VERSION ""

NS_ :

BS_:

BU_: ECU AMKmotor_1

BO_ 3221225472 VECTOR__INDEPENDENT_SIG_MSG: 0 Vector__XXX
 SG_ LogicState_RR : 0|4@1+ (1,0) [0|15] "" Vector__XXX
 SG_ LogicState_RL : 0|4@1+ (1,0) [0|15] "" Vector__XXX
 SG_ LogicState_FR : 0|4@1+ (1,0) [0|15] "" Vector__XXX
 SG_ LogicState_FL : 0|4@1+ (1,0) [0|15] "" Vector__XXX
 SG_ FR_AMK_bEnable : 0|1@1+ (1,0) [0|1] "" Vector__XXX
 SG_ FL_AMK_bEnable : 0|1@1+ (1,0) [0|1] "" Vector__XXX
 SG_ RR_AMK_bEnable : 0|1@1+ (1,0) [0|1] "" Vector__XXX
 SG_ RL_AMK_bEnable : 0|1@1+ (1,0) [0|1] "" Vector__XXX
 SG_ FR_AMK_bQuitInverterOn : 0|1@1+ (1,0) [0|1] "" Vector__XXX
 SG_ FL_AMK_bQuitInverterOn : 0|1@1+ (1,0) [0|1] "" Vector__XXX
 SG_ RR_AMK_bQuitInverterOn : 0|1@1+ (1,0) [0|1] "" Vector__XXX
 SG_ RL_AMK_bQuitInverterOn : 0|1@1+ (1,0) [0|1] "" Vector__XXX
 SG_ FR_AMK_bQuitDcOn : 0|1@1+ (1,0) [0|1] "" Vector__XXX
 SG_ FL_AMK_bQuitDcOn : 0|1@1+ (1,0) [0|1] "" Vector__XXX
 SG_ RR_AMK_bQuitDcOn : 0|1@1+ (1,0) [0|1] "" Vector__XXX
 SG_ RL_AMK_bQuitDcOn : 0|1@1+ (1,0) [0|1] "" Vector__XXX
 SG_ FR_AMK_bSystemReady : 0|1@1+ (1,0) [0|1] "" Vector__XXX
 SG_ FL_AMK_bSystemReady : 0|1@1+ (1,0) [0|1] "" Vector__XXX
 SG_ RR_AMK_bSystemReady : 0|1@1+ (1,0) [0|1] "" Vector__XXX
 SG_ RL_AMK_bSystemReady : 0|1@1+ (1,0) [0|1] "" Vector__XXX
 SG_ FR_AMK_bError : 0|1@1+ (1,0) [0|1] "" Vector__XXX
 SG_ FL_AMK_bError : 0|1@1+ (1,0) [0|1] "" Vector__XXX
 SG_ RR_AMK_bError : 0|1@1+ (1,0) [0|1] "" Vector__XXX
 SG_ RL_AMK_bError : 0|1@1+ (1,0) [0|1] "" Vector__XXX
 SG_ ModeFlag : 0|4@1- (1,0) [-8|7] "" Vector__XXX
 SG_ FR_IGBT_temperature : 0|16@1- (0.1,0) [-3276.8|3276.7] "°" Vector__XXX
 SG_ FL_IGBT_temperature : 0|16@1- (0.1,0) [-3276.8|3276.7] "°" Vector__XXX
 SG_ RR_IGBT_temperature : 0|16@1- (0.1,0) [-3276.8|3276.7] "°" Vector__XXX
 SG_ RL_IGBT_temperature : 0|16@1- (0.1,0) [-3276.8|3276.7] "°" Vector__XXX
 SG_ FR_Inverter_temperature : 0|16@1- (0.1,0) [-3276.8|3276.7] "°" Vector__XXX
 SG_ FL_Inverter_temperature : 0|16@1- (0.1,0) [-3276.8|3276.7] "°" Vector__XXX
 SG_ RR_Inverter_temperature : 0|16@1- (0.1,0) [-3276.8|3276.7] "°" Vector__XXX
 SG_ RL_Inverter_temperature : 0|16@1- (0.1,0) [-3276.8|3276.7] "°" Vector__XXX
 SG_ FR_Motor_temperature : 0|16@1- (0.1,0) [-3276.8|3276.7] "°" Vector__XXX
 SG_ FL_Motor_temperature : 0|16@1- (0.1,0) [-3276.8|3276.7] "°" Vector__XXX
 SG_ RR_Motor_temperature : 0|16@1- (0.1,0) [-3276.8|3276.7] "°" Vector__XXX
 SG_ RL_Motor_temperature : 0|16@1- (0.1,0) [-3276.8|3276.7] "°" Vector__XXX
 SG_ FR_ActualVelocity : 0|16@1- (1,0) [-32768|32767] "" Vector__XXX
 SG_ FL_ActualVelocity : 0|16@1- (1,0) [-32768|32767] "" Vector__XXX
 SG_ RR_ActualVelocity : 0|16@1- (1,0) [-32768|32767] "" Vector__XXX
 SG_ RL_ActualVelocity : 0|16@1- (1,0) [-32768|32767] "" Vector__XXX
 SG_ FR_ActualTorque : 0|16@1- (1,0) [-32768|32767] "0.1%Mn" Vector__XXX
 SG_ FL_ActualTorque : 0|16@1- (1,0) [-32768|32767] "0.1%Mn" Vector__XXX
 SG_ RR_ActualTorque : 0|16@1- (1,0) [-32768|32767] "0.1%Mn" Vector__XXX
 SG_ RL_ActualTorque : 0|16@1- (1,0) [-32768|32767] "0.1%Mn" Vector__XXX
 SG_ OilPressure_Kpa : 0|16@1+ (0.001,0) [0|65.535] "Kpa" Vector__XXX
 SG_ APS_OpenPct : 0|16@1+ (0.1,0) [0|6553.5] "%" Vector__XXX
 SG_ SteeringWheelAngle : 0|16@1- (0.1,0) [-3276.8|3276.7] "deg" Vector__XXX
 SG_ Diagnostic_number_4 : 0|32@1+ (1,0) [0|4294967295] "" Vector__XXX
 SG_ Diagnostic_number_3 : 0|32@1+ (1,0) [0|4294967295] "" Vector__XXX
 SG_ Diagnostic_number_2 : 0|32@1+ (1,0) [0|4294967295] "" Vector__XXX
 SG_ Diagnostic_number_1 : 0|32@1+ (1,0) [0|4294967295] "" Vector__XXX

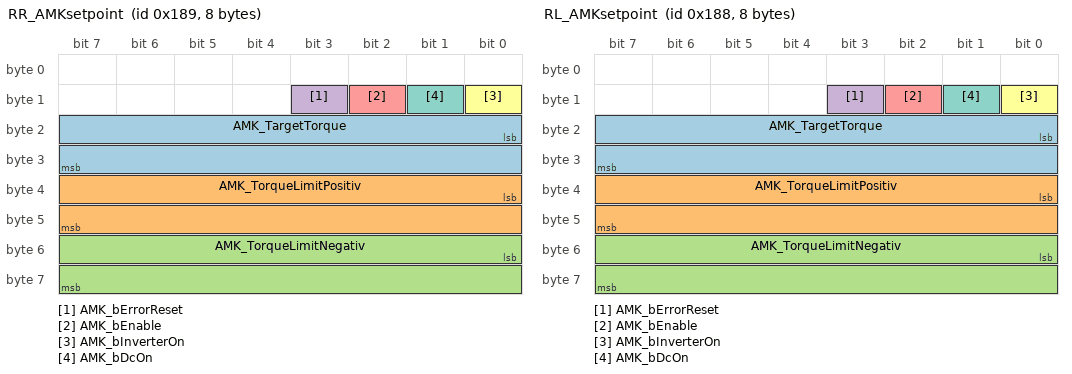
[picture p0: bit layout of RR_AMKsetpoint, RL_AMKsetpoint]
BO_ 393 RR_AMKsetpoint: 8 ECU
 SG_ AMK_TargetTorque : 16|16@1- (1,0) [-32768|32767] ""  AMKmotor_1
 SG_ AMK_TorqueLimitPositiv : 32|16@1- (1,0) [-32768|32767] ""  AMKmotor_1
 SG_ AMK_TorqueLimitNegativ : 48|16@1- (1,0) [-32768|32767] ""  AMKmotor_1
 SG_ AMK_bErrorReset : 11|1@1+ (1,0) [0|1] ""  AMKmotor_1
 SG_ AMK_bEnable : 10|1@1+ (1,0) [0|1] ""  AMKmotor_1
 SG_ AMK_bInverterOn : 8|1@1+ (1,0) [0|1] ""  AMKmotor_1
 SG_ AMK_bDcOn : 9|1@1+ (1,0) [0|1] ""  AMKmotor_1

BO_ 392 RL_AMKsetpoint: 8 ECU
 SG_ AMK_TargetTorque : 16|16@1- (1,0) [-32768|32767] ""  AMKmotor_1
 SG_ AMK_TorqueLimitPositiv : 32|16@1- (1,0) [-32768|32767] ""  AMKmotor_1
 SG_ AMK_TorqueLimitNegativ : 48|16@1- (1,0) [-32768|32767] ""  AMKmotor_1
 SG_ AMK_bErrorReset : 11|1@1+ (1,0) [0|1] ""  AMKmotor_1
 SG_ AMK_bEnable : 10|1@1+ (1,0) [0|1] ""  AMKmotor_1
 SG_ AMK_bInverterOn : 8|1@1+ (1,0) [0|1] ""  AMKmotor_1
 SG_ AMK_bDcOn : 9|1@1+ (1,0) [0|1] ""  AMKmotor_1

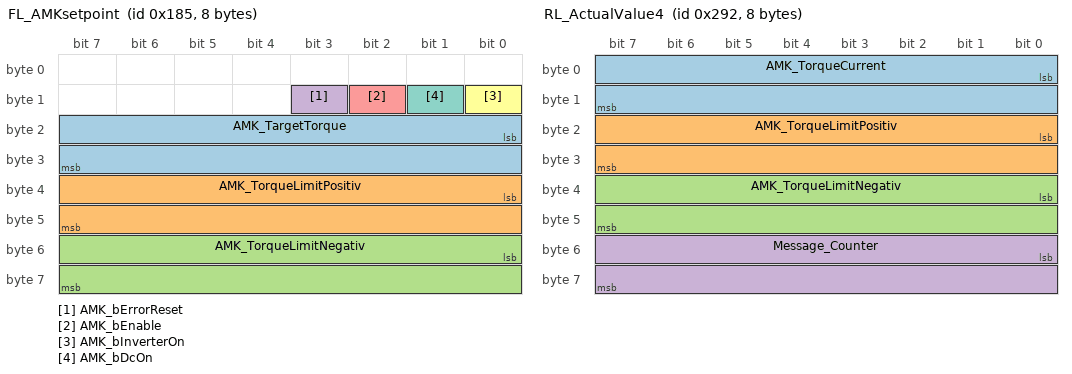
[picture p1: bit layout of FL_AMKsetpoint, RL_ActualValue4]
BO_ 389 FL_AMKsetpoint: 8 ECU
 SG_ AMK_TargetTorque : 16|16@1- (1,0) [-32768|32767] ""  AMKmotor_1
 SG_ AMK_TorqueLimitPositiv : 32|16@1- (1,0) [-32768|32767] ""  AMKmotor_1
 SG_ AMK_TorqueLimitNegativ : 48|16@1- (1,0) [-32768|32767] ""  AMKmotor_1
 SG_ AMK_bErrorReset : 11|1@1+ (1,0) [0|1] ""  AMKmotor_1
 SG_ AMK_bEnable : 10|1@1+ (1,0) [0|1] ""  AMKmotor_1
 SG_ AMK_bInverterOn : 8|1@1+ (1,0) [0|1] ""  AMKmotor_1
 SG_ AMK_bDcOn : 9|1@1+ (1,0) [0|1] ""  AMKmotor_1

BO_ 658 RL_ActualValue4: 8 AMKmotor_1
 SG_ AMK_TorqueCurrent : 0|16@1- (1,0) [-32768|32767] ""  ECU
 SG_ AMK_TorqueLimitPositiv : 16|16@1- (1,0) [-32768|32767] ""  ECU
 SG_ AMK_TorqueLimitNegativ : 32|16@1- (1,0) [-32768|32767] ""  ECU
 SG_ Message_Counter : 48|16@1+ (1,0) [0|65535] ""  ECU

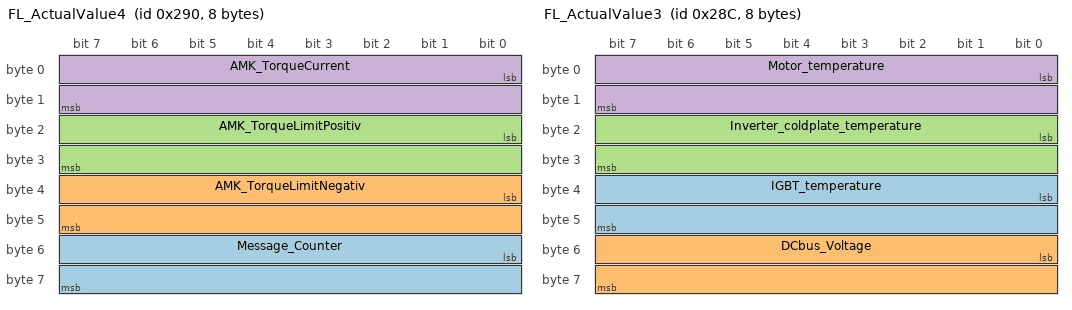
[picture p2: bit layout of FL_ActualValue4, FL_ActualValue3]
BO_ 656 FL_ActualValue4: 8 AMKmotor_1
 SG_ Message_Counter : 48|16@1+ (1,0) [0|65535] ""  ECU
 SG_ AMK_TorqueLimitNegativ : 32|16@1- (1,0) [-32768|32767] ""  ECU
 SG_ AMK_TorqueLimitPositiv : 16|16@1- (1,0) [-32768|32767] ""  ECU
 SG_ AMK_TorqueCurrent : 0|16@1- (1,0) [-32768|32767] ""  ECU

BO_ 652 FL_ActualValue3: 8 AMKmotor_1
 SG_ IGBT_temperature : 32|16@1- (0.1,0) [-3276.8|3276.7] "°"  ECU
 SG_ DCbus_Voltage : 48|16@1+ (1,0) [0|65535] ""  ECU
 SG_ Inverter_coldplate_temperature : 16|16@1- (0.1,0) [-3276.8|3276.7] "°"  ECU
 SG_ Motor_temperature : 0|16@1- (0.1,0) [-3276.8|3276.7] "°"  ECU

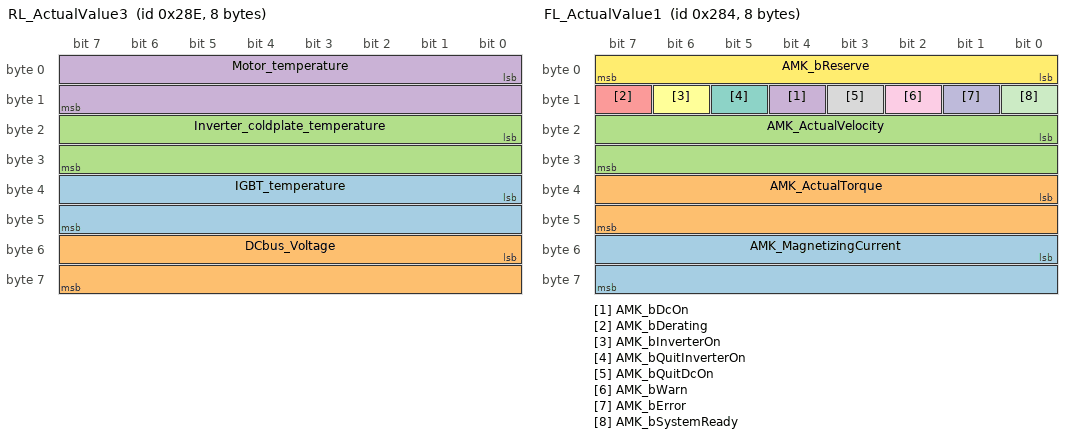
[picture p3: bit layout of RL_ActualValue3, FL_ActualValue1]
BO_ 654 RL_ActualValue3: 8 AMKmotor_1
 SG_ IGBT_temperature : 32|16@1- (0.1,0) [-3276.8|3276.7] "°"  ECU
 SG_ DCbus_Voltage : 48|16@1+ (1,0) [0|65535] ""  ECU
 SG_ Inverter_coldplate_temperature : 16|16@1- (0.1,0) [-3276.8|3276.7] "°"  ECU
 SG_ Motor_temperature : 0|16@1- (0.1,0) [-3276.8|3276.7] "°"  ECU

BO_ 646 FL_ActualValue2: 8 AMKmotor_1
 SG_ Error_info1 : 32|32@1+ (1,0) [0|4294967295] ""  ECU
 SG_ Diagnostic_number_1 : 0|32@1+ (1,0) [0|4294967295] ""  ECU

BO_ 650 RL_ActualValue2: 8 AMKmotor_1
 SG_ Error_info1 : 32|32@1+ (1,0) [0|4294967295] ""  ECU
 SG_ Diagnostic_number_1 : 0|32@1+ (1,0) [0|4294967295] ""  ECU

BO_ 644 FL_ActualValue1: 8 AMKmotor_1
 SG_ AMK_MagnetizingCurrent : 48|16@1- (1,0) [-32768|32767] ""  ECU
 SG_ AMK_ActualTorque : 32|16@1- (1,0) [-32768|32767] "0.1%Mn"  ECU
 SG_ AMK_ActualVelocity : 16|16@1- (1,0) [-32768|32767] ""  ECU
 SG_ AMK_bDcOn : 12|1@1+ (1,0) [0|1] ""  ECU
 SG_ AMK_bDerating : 15|1@1+ (1,0) [0|1] ""  ECU
 SG_ AMK_bInverterOn : 14|1@1+ (1,0) [0|1] ""  ECU
 SG_ AMK_bQuitInverterOn : 13|1@1+ (1,0) [0|1] ""  ECU
 SG_ AMK_bQuitDcOn : 11|1@1+ (1,0) [0|1] ""  ECU
 SG_ AMK_bWarn : 10|1@1+ (1,0) [0|1] ""  ECU
 SG_ AMK_bError : 9|1@1+ (1,0) [0|1] ""  ECU
 SG_ AMK_bSystemReady : 8|1@1+ (1,0) [0|1] ""  ECU
 SG_ AMK_bReserve : 0|8@1+ (1,0) [0|255] ""  ECU

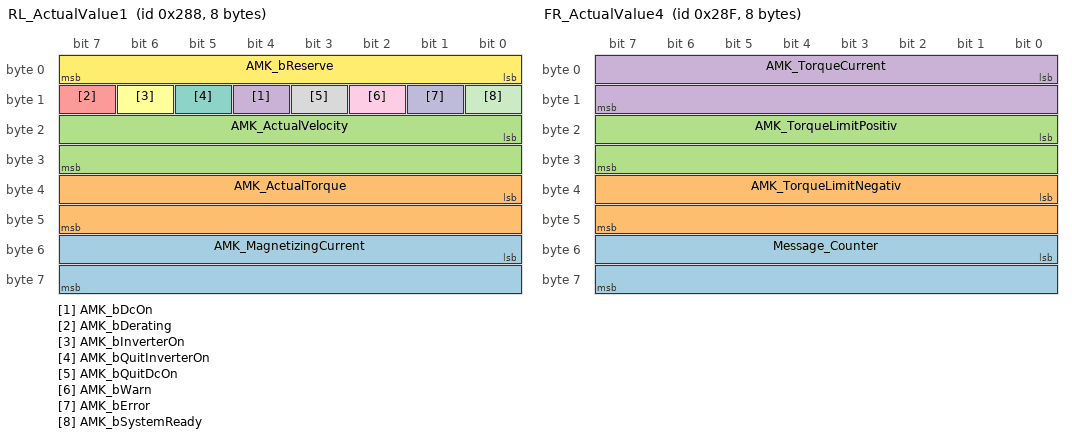
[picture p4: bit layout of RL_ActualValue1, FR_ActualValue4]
BO_ 648 RL_ActualValue1: 8 AMKmotor_1
 SG_ AMK_MagnetizingCurrent : 48|16@1- (1,0) [-32768|32767] ""  ECU
 SG_ AMK_ActualTorque : 32|16@1- (1,0) [-32768|32767] "0.1%Mn"  ECU
 SG_ AMK_ActualVelocity : 16|16@1- (1,0) [-32768|32767] ""  ECU
 SG_ AMK_bDcOn : 12|1@1+ (1,0) [0|1] ""  ECU
 SG_ AMK_bDerating : 15|1@1+ (1,0) [0|1] ""  ECU
 SG_ AMK_bInverterOn : 14|1@1+ (1,0) [0|1] ""  ECU
 SG_ AMK_bQuitInverterOn : 13|1@1+ (1,0) [0|1] ""  ECU
 SG_ AMK_bQuitDcOn : 11|1@1+ (1,0) [0|1] ""  ECU
 SG_ AMK_bWarn : 10|1@1+ (1,0) [0|1] ""  ECU
 SG_ AMK_bError : 9|1@1+ (1,0) [0|1] ""  ECU
 SG_ AMK_bSystemReady : 8|1@1+ (1,0) [0|1] ""  ECU
 SG_ AMK_bReserve : 0|8@1+ (1,0) [0|255] ""  ECU

BO_ 655 FR_ActualValue4: 8 AMKmotor_1
 SG_ Message_Counter : 48|16@1+ (1,0) [0|65535] ""  ECU
 SG_ AMK_TorqueLimitNegativ : 32|16@1- (1,0) [-32768|32767] ""  ECU
 SG_ AMK_TorqueLimitPositiv : 16|16@1- (1,0) [-32768|32767] ""  ECU
 SG_ AMK_TorqueCurrent : 0|16@1- (1,0) [-32768|32767] ""  ECU

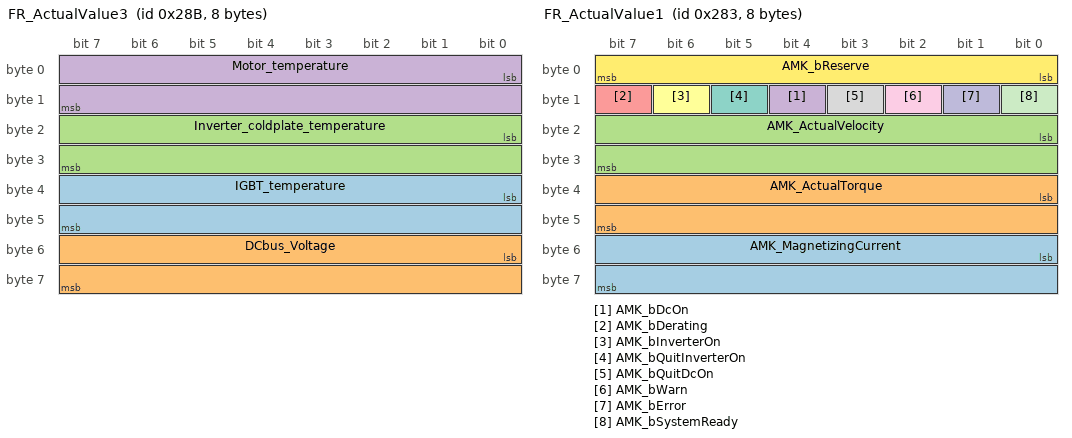
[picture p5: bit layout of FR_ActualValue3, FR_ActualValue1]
BO_ 651 FR_ActualValue3: 8 AMKmotor_1
 SG_ IGBT_temperature : 32|16@1- (0.1,0) [-3276.8|3276.7] "°"  ECU
 SG_ DCbus_Voltage : 48|16@1+ (1,0) [0|65535] ""  ECU
 SG_ Inverter_coldplate_temperature : 16|16@1- (0.1,0) [-3276.8|3276.7] "°"  ECU
 SG_ Motor_temperature : 0|16@1- (0.1,0) [-3276.8|3276.7] "°"  ECU

BO_ 645 FR_ActualValue2: 8 AMKmotor_1
 SG_ Error_info1 : 32|32@1+ (1,0) [0|4294967295] ""  ECU
 SG_ Diagnostic_number_1 : 0|32@1+ (1,0) [0|4294967295] ""  ECU

BO_ 643 FR_ActualValue1: 8 AMKmotor_1
 SG_ AMK_MagnetizingCurrent : 48|16@1- (1,0) [-32768|32767] ""  ECU
 SG_ AMK_ActualTorque : 32|16@1- (1,0) [-32768|32767] "0.1%Mn"  ECU
 SG_ AMK_ActualVelocity : 16|16@1- (1,0) [-32768|32767] ""  ECU
 SG_ AMK_bDcOn : 12|1@1+ (1,0) [0|1] ""  ECU
 SG_ AMK_bDerating : 15|1@1+ (1,0) [0|1] ""  ECU
 SG_ AMK_bInverterOn : 14|1@1+ (1,0) [0|1] ""  ECU
 SG_ AMK_bQuitInverterOn : 13|1@1+ (1,0) [0|1] ""  ECU
 SG_ AMK_bQuitDcOn : 11|1@1+ (1,0) [0|1] ""  ECU
 SG_ AMK_bWarn : 10|1@1+ (1,0) [0|1] ""  ECU
 SG_ AMK_bError : 9|1@1+ (1,0) [0|1] ""  ECU
 SG_ AMK_bSystemReady : 8|1@1+ (1,0) [0|1] ""  ECU
 SG_ AMK_bReserve : 0|8@1+ (1,0) [0|255] ""  ECU

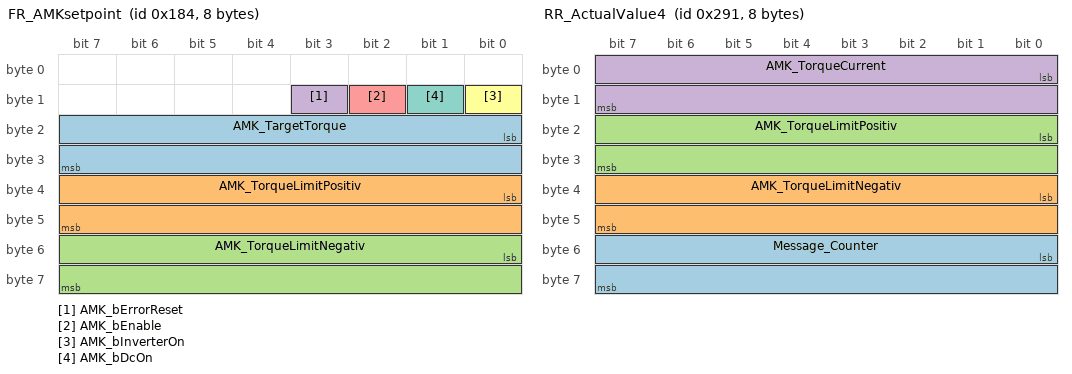
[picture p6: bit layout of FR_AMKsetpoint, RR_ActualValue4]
BO_ 388 FR_AMKsetpoint: 8 ECU
 SG_ AMK_TargetTorque : 16|16@1- (1,0) [-32768|32767] ""  AMKmotor_1
 SG_ AMK_TorqueLimitPositiv : 32|16@1- (1,0) [-32768|32767] ""  AMKmotor_1
 SG_ AMK_TorqueLimitNegativ : 48|16@1- (1,0) [-32768|32767] ""  AMKmotor_1
 SG_ AMK_bErrorReset : 11|1@1+ (1,0) [0|1] ""  AMKmotor_1
 SG_ AMK_bEnable : 10|1@1+ (1,0) [0|1] ""  AMKmotor_1
 SG_ AMK_bInverterOn : 8|1@1+ (1,0) [0|1] ""  AMKmotor_1
 SG_ AMK_bDcOn : 9|1@1+ (1,0) [0|1] ""  AMKmotor_1

BO_ 657 RR_ActualValue4: 8 AMKmotor_1
 SG_ Message_Counter : 48|16@1+ (1,0) [0|65535] ""  ECU
 SG_ AMK_TorqueLimitNegativ : 32|16@1- (1,0) [-32768|32767] ""  ECU
 SG_ AMK_TorqueLimitPositiv : 16|16@1- (1,0) [-32768|32767] ""  ECU
 SG_ AMK_TorqueCurrent : 0|16@1- (1,0) [-32768|32767] ""  ECU

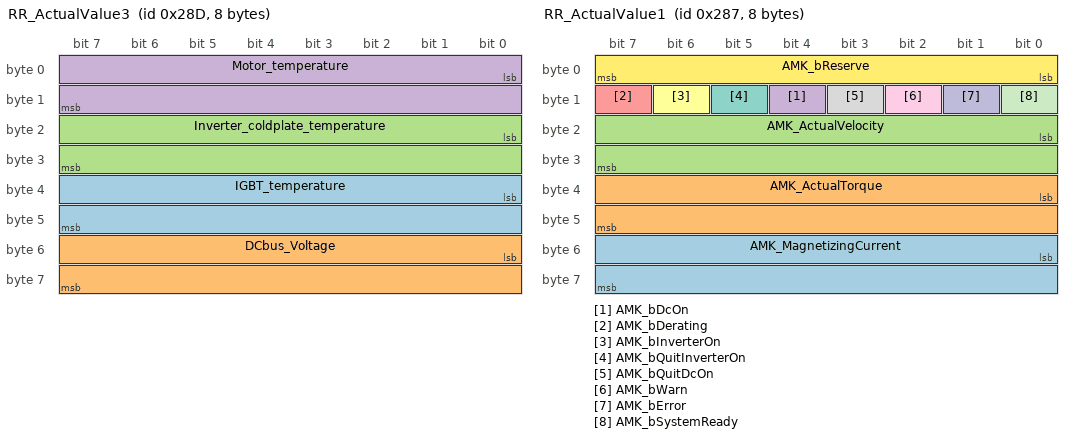
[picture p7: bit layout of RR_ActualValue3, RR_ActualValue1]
BO_ 653 RR_ActualValue3: 8 AMKmotor_1
 SG_ IGBT_temperature : 32|16@1- (0.1,0) [-3276.8|3276.7] "°"  ECU
 SG_ DCbus_Voltage : 48|16@1+ (1,0) [0|65535] ""  ECU
 SG_ Inverter_coldplate_temperature : 16|16@1- (0.1,0) [-3276.8|3276.7] "°"  ECU
 SG_ Motor_temperature : 0|16@1- (0.1,0) [-3276.8|3276.7] "°"  ECU

BO_ 649 RR_ActualValue2: 8 AMKmotor_1
 SG_ Error_info1 : 32|32@1+ (1,0) [0|4294967295] ""  ECU
 SG_ Diagnostic_number_1 : 0|32@1+ (1,0) [0|4294967295] ""  ECU

BO_ 647 RR_ActualValue1: 8 AMKmotor_1
 SG_ AMK_MagnetizingCurrent : 48|16@1- (1,0) [-32768|32767] ""  ECU
 SG_ AMK_ActualTorque : 32|16@1- (1,0) [-32768|32767] "0.1%Mn"  ECU
 SG_ AMK_ActualVelocity : 16|16@1- (1,0) [-32768|32767] ""  ECU
 SG_ AMK_bDcOn : 12|1@1+ (1,0) [0|1] ""  ECU
 SG_ AMK_bDerating : 15|1@1+ (1,0) [0|1] ""  ECU
 SG_ AMK_bInverterOn : 14|1@1+ (1,0) [0|1] ""  ECU
 SG_ AMK_bQuitInverterOn : 13|1@1+ (1,0) [0|1] ""  ECU
 SG_ AMK_bQuitDcOn : 11|1@1+ (1,0) [0|1] ""  ECU
 SG_ AMK_bWarn : 10|1@1+ (1,0) [0|1] ""  ECU
 SG_ AMK_bError : 9|1@1+ (1,0) [0|1] ""  ECU
 SG_ AMK_bSystemReady : 8|1@1+ (1,0) [0|1] ""  ECU
 SG_ AMK_bReserve : 0|8@1+ (1,0) [0|255] ""  ECU

CM_ BO_ 3221225472 "This is a message for not used signals, created by Vector CANdb++ DBC OLE DB Provider.";
CM_ SG_ 3221225472 FR_AMK_bEnable "表示电机是否使能";
CM_ SG_ 3221225472 FR_IGBT_temperature "单位：摄氏度";
CM_ SG_ 3221225472 FR_Inverter_temperature "单位：摄氏度";
CM_ SG_ 3221225472 FR_Motor_temperature "单位：摄氏度";
CM_ SG_ 3221225472 FR_ActualTorque "右前实际扭矩";
CM_ SG_ 3221225472 OilPressure_Kpa "油压信号，单位是Kpa";
CM_ SG_ 3221225472 APS_OpenPct "0~100%表示油门开度";
CM_ SG_ 3221225472 SteeringWheelAngle "方向盘转角从-137到136deg";
CM_ SG_ 393 AMK_TargetTorque "目标扭矩，Toqruqe setpoint";
CM_ SG_ 393 AMK_bErrorReset "表示电机消错，前提是setpoint其他值都得为0";
CM_ SG_ 393 AMK_bEnable "表示电机是否使能";
CM_ SG_ 392 AMK_TargetTorque "目标扭矩，Toqruqe setpoint";
CM_ SG_ 392 AMK_bErrorReset "表示电机消错，前提是setpoint其他值都得为0";
CM_ SG_ 392 AMK_bEnable "表示电机是否使能";
CM_ SG_ 389 AMK_TargetTorque "目标扭矩，Toqruqe setpoint";
CM_ SG_ 389 AMK_bErrorReset "表示电机消错，前提是setpoint其他值都得为0";
CM_ SG_ 389 AMK_bEnable "表示电机是否使能";
CM_ SG_ 652 IGBT_temperature "单位：摄氏度";
CM_ SG_ 652 Inverter_coldplate_temperature "单位：摄氏度";
CM_ SG_ 652 Motor_temperature "单位：摄氏度";
CM_ SG_ 654 IGBT_temperature "单位：摄氏度";
CM_ SG_ 654 Inverter_coldplate_temperature "单位：摄氏度";
CM_ SG_ 654 Motor_temperature "单位：摄氏度";
CM_ SG_ 644 AMK_ActualTorque "右前实际扭矩";
CM_ SG_ 648 AMK_ActualTorque "左后实际扭矩";
CM_ SG_ 651 IGBT_temperature "单位：摄氏度";
CM_ SG_ 651 Inverter_coldplate_temperature "单位：摄氏度";
CM_ SG_ 651 Motor_temperature "单位：摄氏度";
CM_ SG_ 643 AMK_ActualTorque "左前实际扭矩";
CM_ SG_ 388 AMK_TargetTorque "目标扭矩，Toqruqe setpoint";
CM_ SG_ 388 AMK_bErrorReset "表示电机消错，前提是setpoint其他值都得为0";
CM_ SG_ 388 AMK_bEnable "表示电机是否使能";
CM_ SG_ 653 IGBT_temperature "单位：摄氏度";
CM_ SG_ 653 Inverter_coldplate_temperature "单位：摄氏度";
CM_ SG_ 653 Motor_temperature "单位：摄氏度";
CM_ SG_ 647 AMK_ActualTorque "右后实际扭矩";
BA_DEF_  "BusType" STRING ;
BA_DEF_DEF_  "BusType" "CAN";
